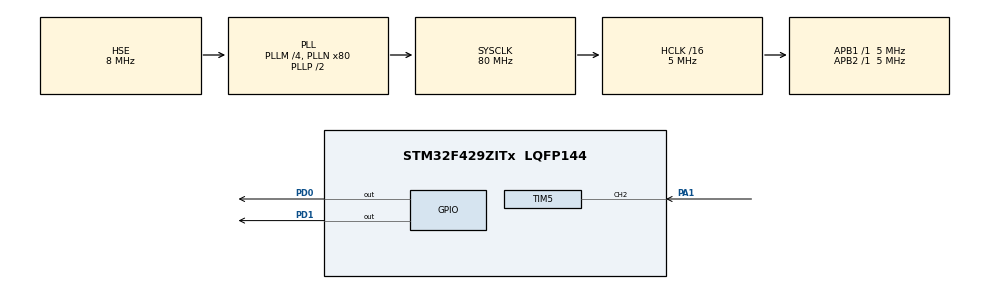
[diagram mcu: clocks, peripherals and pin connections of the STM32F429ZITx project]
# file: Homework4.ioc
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Mcu.Family=STM32F4
Mcu.Name=STM32F429ZITx
Mcu.Package=LQFP144
NVIC.PriorityGroup=NVIC_PRIORITYGROUP_4
NVIC.TIM5_IRQn=true\:0\:0\:false\:false\:true\:true\:true\:true
PA1.Signal=S_TIM5_CH2
PD0.Signal=GPIO_Output
PD1.Signal=GPIO_Output
PH0/OSC_IN.Mode=HSE-External-Oscillator
PH0/OSC_IN.Signal=RCC_OSC_IN
PH1/OSC_OUT.Mode=HSE-External-Oscillator
PH1/OSC_OUT.Signal=RCC_OSC_OUT
ProjectManager.HeapSize=0x200
ProjectManager.StackSize=0x400
ProjectManager.TargetToolchain=EWARM V8.50
RCC.48MHZClocksFreq_Value=40000000
RCC.AHBCLKDivider=RCC_SYSCLK_DIV16
RCC.AHBFreq_Value=5000000
RCC.APB1Freq_Value=5000000
RCC.APB1TimFreq_Value=5000000
RCC.APB2Freq_Value=5000000
RCC.APB2TimFreq_Value=5000000
RCC.CortexFreq_Value=5000000
RCC.HCLKFreq_Value=5000000
RCC.HSE_VALUE=8000000
RCC.HSI_VALUE=16000000
RCC.LSE_VALUE=32768
RCC.PLLM=4
RCC.PLLN=80
RCC.PLLSourceVirtual=RCC_PLLSOURCE_HSE
RCC.SYSCLKFreq_VALUE=80000000
RCC.SYSCLKSource=RCC_SYSCLKSOURCE_PLLCLK
RCC.VCOOutputFreq_Value=160000000
SH.S_TIM5_CH2.0=TIM5_CH2,Input_Capture2_from_TI2
TIM5.Channel-Input_Capture2_from_TI2=TIM_CHANNEL_2
board=custom

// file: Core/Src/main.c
/* USER CODE BEGIN Header */
/**
  ******************************************************************************
  * @file           : main.c
  * @brief          : Main program body
  ******************************************************************************
  * @attention
  *
  * Copyright (c) 2023 STMicroelectronics.
  * All rights reserved.
  *
  * This software is licensed under terms that can be found in the LICENSE file
  * in the root directory of this software component.
  * If no LICENSE file comes with this software, it is provided AS-IS.
  *
  ******************************************************************************
  */
/* USER CODE END Header */
#include "main.h"

TIM_HandleTypeDef htim5;

/* USER CODE BEGIN PV */
float freq = 0; // define a variable for the
/* USER CODE END PV */

void SystemClock_Config(void);
static void MX_GPIO_Init(void);
static void MX_TIM5_Init(void);

int main(void)
{

  /* MCU Configuration--------------------------------------------------------*/

  /* Reset of all peripherals, Initializes the Flash interface and the Systick. */
  HAL_Init();

  /* Configure the system clock */
  SystemClock_Config();

  /* Initialize all configured peripherals */
  MX_GPIO_Init();
  MX_TIM5_Init();

  /* Infinite loop */
  /* USER CODE BEGIN WHILE */
  HAL_TIM_IC_Start_IT(&htim5, TIM_CHANNEL_2); // start the timer
  HAL_GPIO_WritePin(GPIOD, GPIO_PIN_0, GPIO_PIN_SET);
  HAL_GPIO_WritePin(GPIOD, GPIO_PIN_1, GPIO_PIN_SET);
  // set LED0=LED1=H to start out
  while (1)
  {
    /* USER CODE END WHILE */

  }
}

void SystemClock_Config(void)
{
  RCC_OscInitTypeDef RCC_OscInitStruct = {0};
  RCC_ClkInitTypeDef RCC_ClkInitStruct = {0};

  /** Configure the main internal regulator output voltage
  */
  __HAL_RCC_PWR_CLK_ENABLE();
  __HAL_PWR_VOLTAGESCALING_CONFIG(PWR_REGULATOR_VOLTAGE_SCALE3);

  /** Initializes the RCC Oscillators according to the specified parameters
  * in the RCC_OscInitTypeDef structure.
  */
  RCC_OscInitStruct.OscillatorType = RCC_OSCILLATORTYPE_HSE;
  RCC_OscInitStruct.HSEState = RCC_HSE_ON;
  RCC_OscInitStruct.PLL.PLLState = RCC_PLL_ON;
  RCC_OscInitStruct.PLL.PLLSource = RCC_PLLSOURCE_HSE;
  RCC_OscInitStruct.PLL.PLLM = 4;
  RCC_OscInitStruct.PLL.PLLN = 80;
  RCC_OscInitStruct.PLL.PLLP = RCC_PLLP_DIV2;
  RCC_OscInitStruct.PLL.PLLQ = 4;
  if (HAL_RCC_OscConfig(&RCC_OscInitStruct) != HAL_OK)
  {
    Error_Handler();
  }

  /** Initializes the CPU, AHB and APB buses clocks
  */
  RCC_ClkInitStruct.ClockType = RCC_CLOCKTYPE_HCLK|RCC_CLOCKTYPE_SYSCLK
                              |RCC_CLOCKTYPE_PCLK1|RCC_CLOCKTYPE_PCLK2;
  RCC_ClkInitStruct.SYSCLKSource = RCC_SYSCLKSOURCE_PLLCLK;
  RCC_ClkInitStruct.AHBCLKDivider = RCC_SYSCLK_DIV16;
  RCC_ClkInitStruct.APB1CLKDivider = RCC_HCLK_DIV1;
  RCC_ClkInitStruct.APB2CLKDivider = RCC_HCLK_DIV1;

  if (HAL_RCC_ClockConfig(&RCC_ClkInitStruct, FLASH_LATENCY_0) != HAL_OK)
  {
    Error_Handler();
  }
}

static void MX_TIM5_Init(void)
{

  TIM_MasterConfigTypeDef sMasterConfig = {0};
  TIM_IC_InitTypeDef sConfigIC = {0};

  htim5.Instance = TIM5;
  htim5.Init.Prescaler = 0;
  htim5.Init.CounterMode = TIM_COUNTERMODE_UP;
  htim5.Init.Period = 4294967295;
  htim5.Init.ClockDivision = TIM_CLOCKDIVISION_DIV1;
  htim5.Init.AutoReloadPreload = TIM_AUTORELOAD_PRELOAD_DISABLE;
  if (HAL_TIM_IC_Init(&htim5) != HAL_OK)
  {
    Error_Handler();
  }
  sMasterConfig.MasterOutputTrigger = TIM_TRGO_RESET;
  sMasterConfig.MasterSlaveMode = TIM_MASTERSLAVEMODE_DISABLE;
  if (HAL_TIMEx_MasterConfigSynchronization(&htim5, &sMasterConfig) != HAL_OK)
  {
    Error_Handler();
  }
  sConfigIC.ICPolarity = TIM_INPUTCHANNELPOLARITY_RISING;
  sConfigIC.ICSelection = TIM_ICSELECTION_DIRECTTI;
  sConfigIC.ICPrescaler = TIM_ICPSC_DIV1;
  sConfigIC.ICFilter = 0;
  if (HAL_TIM_IC_ConfigChannel(&htim5, &sConfigIC, TIM_CHANNEL_2) != HAL_OK)
  {
    Error_Handler();
  }

}

static void MX_GPIO_Init(void)
{
  GPIO_InitTypeDef GPIO_InitStruct = {0};

  /* GPIO Ports Clock Enable */
  __HAL_RCC_GPIOH_CLK_ENABLE();
  __HAL_RCC_GPIOA_CLK_ENABLE();
  __HAL_RCC_GPIOD_CLK_ENABLE();

  /*Configure GPIO pin Output Level */
  HAL_GPIO_WritePin(GPIOD, GPIO_PIN_0|GPIO_PIN_1, GPIO_PIN_RESET);

  /*Configure GPIO pins : PD0 PD1 */
  GPIO_InitStruct.Pin = GPIO_PIN_0|GPIO_PIN_1;
  GPIO_InitStruct.Mode = GPIO_MODE_OUTPUT_PP;
  GPIO_InitStruct.Pull = GPIO_NOPULL;
  GPIO_InitStruct.Speed = GPIO_SPEED_FREQ_LOW;
  HAL_GPIO_Init(GPIOD, &GPIO_InitStruct);

}

void Error_Handler(void)
{
  __disable_irq();
  while (1)
  {
  }
}
